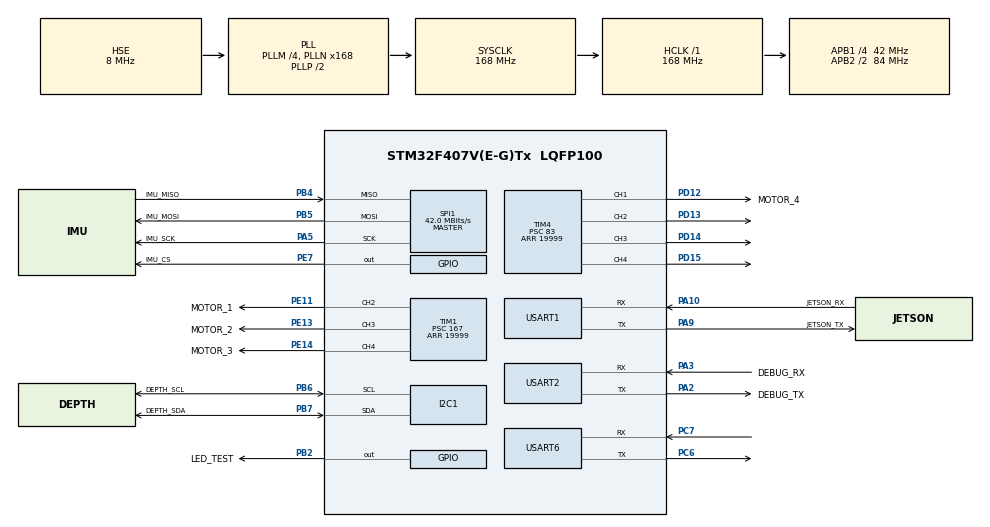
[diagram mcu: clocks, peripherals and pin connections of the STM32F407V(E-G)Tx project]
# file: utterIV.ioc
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Dma.Request0=USART1_TX
Dma.USART1_TX.0.Direction=DMA_MEMORY_TO_PERIPH
Dma.USART1_TX.0.FIFOMode=DMA_FIFOMODE_DISABLE
Dma.USART1_TX.0.Instance=DMA2_Stream7
Dma.USART1_TX.0.MemDataAlignment=DMA_MDATAALIGN_BYTE
Dma.USART1_TX.0.MemInc=DMA_MINC_ENABLE
Dma.USART1_TX.0.Mode=DMA_NORMAL
Dma.USART1_TX.0.PeriphDataAlignment=DMA_PDATAALIGN_BYTE
Dma.USART1_TX.0.PeriphInc=DMA_PINC_DISABLE
Dma.USART1_TX.0.Priority=DMA_PRIORITY_LOW
FREERTOS.Tasks01=startTask,24,300,StartDefaultTask,Default,NULL,Dynamic,NULL,NULL
FREERTOS.configENABLE_FPU=0
Mcu.Family=STM32F4
Mcu.Name=STM32F407V(E-G)Tx
Mcu.Package=LQFP100
NVIC.DMA2_Stream7_IRQn=true\:5\:0\:false\:false\:true\:true\:false\:true\:true
NVIC.PriorityGroup=NVIC_PRIORITYGROUP_4
NVIC.TIM5_IRQn=true\:15\:0\:false\:false\:true\:false\:false\:true\:true
NVIC.TimeBase=TIM5_IRQn
NVIC.TimeBaseIP=TIM5
NVIC.USART1_IRQn=true\:5\:0\:false\:false\:true\:true\:true\:true\:true
NVIC.USART6_IRQn=true\:5\:0\:false\:false\:true\:true\:true\:true\:true
PA10.GPIO_Label=JETSON_RX
PA10.Mode=Asynchronous
PA10.Signal=USART1_RX
PA13.Mode=Serial_Wire
PA13.Signal=SYS_JTMS-SWDIO
PA14.Mode=Serial_Wire
PA14.Signal=SYS_JTCK-SWCLK
PA2.GPIO_Label=DEBUG_TX
PA2.Mode=Asynchronous
PA2.Signal=USART2_TX
PA3.GPIO_Label=DEBUG_RX
PA3.Mode=Asynchronous
PA3.Signal=USART2_RX
PA5.GPIO_Label=IMU_SCK
PA5.Mode=Full_Duplex_Master
PA5.Signal=SPI1_SCK
PA9.GPIO_Label=JETSON_TX
PA9.Mode=Asynchronous
PA9.Signal=USART1_TX
PB2.GPIO_Label=LED_TEST
PB2.PinState=GPIO_PIN_SET
PB2.Signal=GPIO_Output
PB4.GPIO_Label=IMU_MISO
PB4.Mode=Full_Duplex_Master
PB4.Signal=SPI1_MISO
PB5.GPIO_Label=IMU_MOSI
PB5.Mode=Full_Duplex_Master
PB5.Signal=SPI1_MOSI
PB6.GPIO_Label=DEPTH_SCL
PB6.GPIO_Pu=GPIO_NOPULL
PB6.Mode=I2C
PB6.Signal=I2C1_SCL
PB7.GPIO_Label=DEPTH_SDA
PB7.GPIO_Pu=GPIO_NOPULL
PB7.Mode=I2C
PB7.Signal=I2C1_SDA
PC14-OSC32_IN.Mode=LSE-External-Oscillator
PC14-OSC32_IN.Signal=RCC_OSC32_IN
PC15-OSC32_OUT.Mode=LSE-External-Oscillator
PC15-OSC32_OUT.Signal=RCC_OSC32_OUT
PC6.Mode=Asynchronous
PC6.Signal=USART6_TX
PC7.Mode=Asynchronous
PC7.Signal=USART6_RX
PD12.GPIO_Label=MOTOR_4
PD12.Signal=S_TIM4_CH1
PD13.Signal=S_TIM4_CH2
PD14.Signal=S_TIM4_CH3
PD15.Signal=S_TIM4_CH4
PE11.GPIO_Label=MOTOR_1
PE11.Signal=S_TIM1_CH2
PE13.GPIO_Label=MOTOR_2
PE13.Signal=S_TIM1_CH3
PE14.GPIO_Label=MOTOR_3
PE14.Signal=S_TIM1_CH4
PE7.GPIO_Label=IMU_CS
PE7.GPIO_PuPd=GPIO_PULLUP
PE7.PinState=GPIO_PIN_SET
PE7.Signal=GPIO_Output
PH0-OSC_IN.Mode=HSE-External-Oscillator
PH0-OSC_IN.Signal=RCC_OSC_IN
PH1-OSC_OUT.Mode=HSE-External-Oscillator
PH1-OSC_OUT.Signal=RCC_OSC_OUT
ProjectManager.HeapSize=0x200
ProjectManager.StackSize=0x400
ProjectManager.TargetToolchain=MDK-ARM V5.32
RCC.48MHZClocksFreq_Value=84000000
RCC.AHBFreq_Value=168000000
RCC.APB1CLKDivider=RCC_HCLK_DIV4
RCC.APB1Freq_Value=42000000
RCC.APB1TimFreq_Value=84000000
RCC.APB2CLKDivider=RCC_HCLK_DIV2
RCC.APB2Freq_Value=84000000
RCC.APB2TimFreq_Value=168000000
RCC.CortexFreq_Value=168000000
RCC.HCLKFreq_Value=168000000
RCC.HSE_VALUE=8000000
RCC.HSI_VALUE=16000000
RCC.PLLM=4
RCC.PLLN=168
RCC.PLLSourceVirtual=RCC_PLLSOURCE_HSE
RCC.SYSCLKFreq_VALUE=168000000
RCC.SYSCLKSource=RCC_SYSCLKSOURCE_PLLCLK
RCC.VCOOutputFreq_Value=336000000
SH.S_TIM1_CH2.0=TIM1_CH2,PWM Generation2 CH2
SH.S_TIM1_CH3.0=TIM1_CH3,PWM Generation3 CH3
SH.S_TIM1_CH4.0=TIM1_CH4,PWM Generation4 CH4
SH.S_TIM4_CH1.0=TIM4_CH1,PWM Generation1 CH1
SH.S_TIM4_CH2.0=TIM4_CH2,PWM Generation2 CH2
SH.S_TIM4_CH3.0=TIM4_CH3,PWM Generation3 CH3
SH.S_TIM4_CH4.0=TIM4_CH4,PWM Generation4 CH4
SPI1.BaudRatePrescaler=SPI_BAUDRATEPRESCALER_2
SPI1.CalculateBaudRate=42.0 MBits/s
SPI1.Direction=SPI_DIRECTION_2LINES
SPI1.Mode=SPI_MODE_MASTER
SPI1.VirtualType=VM_MASTER
TIM1.AutoReloadPreload=TIM_AUTORELOAD_PRELOAD_ENABLE
TIM1.Channel-PWM\ Generation2\ CH2=TIM_CHANNEL_2
TIM1.Channel-PWM\ Generation3\ CH3=TIM_CHANNEL_3
TIM1.Channel-PWM\ Generation4\ CH4=TIM_CHANNEL_4
TIM1.Period=19999
TIM1.Prescaler=167
TIM1.Pulse-PWM\ Generation2\ CH2=1500
TIM1.Pulse-PWM\ Generation3\ CH3=1500
TIM1.Pulse-PWM\ Generation4\ CH4=1500
TIM4.Channel-PWM\ Generation1\ CH1=TIM_CHANNEL_1
TIM4.Channel-PWM\ Generation2\ CH2=TIM_CHANNEL_2
TIM4.Channel-PWM\ Generation3\ CH3=TIM_CHANNEL_3
TIM4.Channel-PWM\ Generation4\ CH4=TIM_CHANNEL_4
TIM4.Period=19999
TIM4.Prescaler=83
TIM4.Pulse-PWM\ Generation1\ CH1=1500
TIM4.Pulse-PWM\ Generation2\ CH2=1500
TIM4.Pulse-PWM\ Generation3\ CH3=1500
TIM4.Pulse-PWM\ Generation4\ CH4=1500
USART1.VirtualMode=VM_ASYNC
USART2.VirtualMode=VM_ASYNC
USART6.VirtualMode=VM_ASYNC
VP_FREERTOS_VS_CMSIS_V2.Mode=CMSIS_V2
VP_SYS_VS_tim5.Mode=TIM5
board=custom

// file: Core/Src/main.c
/* USER CODE BEGIN Header */
/**
  ******************************************************************************
  * @file           : main.c
  * @brief          : Main program body
  ******************************************************************************
  * @attention
  *
  * Copyright (c) 2026 STMicroelectronics.
  * All rights reserved.
  *
  * This software is licensed under terms that can be found in the LICENSE file
  * in the root directory of this software component.
  * If no LICENSE file comes with this software, it is provided AS-IS.
  *
  ******************************************************************************
  */
/* USER CODE END Header */
#include "main.h"
#include "cmsis_os.h"

/* USER CODE BEGIN Includes */

#include "system.h"

/* USER CODE END Includes */

/* USER CODE BEGIN PM */
#include <stdio.h>

#pragma import(__use_no_semihosting)
struct __FILE { int handle; };
FILE __stdout;
void _sys_exit(int return_code)
{
    while(1);
}

/* USER CODE END PM */

I2C_HandleTypeDef hi2c1;

SPI_HandleTypeDef hspi1;

TIM_HandleTypeDef htim1;
TIM_HandleTypeDef htim4;

UART_HandleTypeDef huart1;
UART_HandleTypeDef huart2;
UART_HandleTypeDef huart6;
DMA_HandleTypeDef hdma_usart1_tx;

/* Definitions for startTask */
osThreadId_t startTaskHandle;
const osThreadAttr_t startTask_attributes = {
  .name = "startTask",
  .stack_size = 300 * 4,
  .priority = (osPriority_t) osPriorityNormal,
};

void SystemClock_Config(void);
static void MX_GPIO_Init(void);
static void MX_DMA_Init(void);
static void MX_SPI1_Init(void);
static void MX_TIM1_Init(void);
static void MX_USART1_UART_Init(void);
static void MX_USART2_UART_Init(void);
static void MX_TIM4_Init(void);
static void MX_I2C1_Init(void);
static void MX_USART6_UART_Init(void);
void StartDefaultTask(void *argument);

/* USER CODE BEGIN 0 */
//int fputc(int ch, FILE *f)
//{
//    HAL_UART_Transmit(&huart1, (uint8_t *)&ch, 1, HAL_MAX_DELAY);
//    return ch;
//}
/* USER CODE END 0 */

int main(void)
{

  /* MCU Configuration--------------------------------------------------------*/

  /* Reset of all peripherals, Initializes the Flash interface and the Systick. */
  HAL_Init();

  /* Configure the system clock */
  SystemClock_Config();

  /* Initialize all configured peripherals */
  MX_GPIO_Init();
  MX_DMA_Init();
  MX_SPI1_Init();
  MX_TIM1_Init();
  MX_USART1_UART_Init();
  MX_USART2_UART_Init();
  MX_TIM4_Init();
  MX_I2C1_Init();
  MX_USART6_UART_Init();
  /* USER CODE BEGIN 2 */
  systemInit();

  /* USER CODE END 2 */

  /* Init scheduler */
  osKernelInitialize();

  /* Create the thread(s) */
  /* creation of startTask */
  startTaskHandle = osThreadNew(StartDefaultTask, NULL, &startTask_attributes);

  /* Start scheduler */
  osKernelStart();

  /* We should never get here as control is now taken by the scheduler */

  /* Infinite loop */
  while (1)
  {

  }
}

void SystemClock_Config(void)
{
  RCC_OscInitTypeDef RCC_OscInitStruct = {0};
  RCC_ClkInitTypeDef RCC_ClkInitStruct = {0};

  /** Configure the main internal regulator output voltage
  */
  __HAL_RCC_PWR_CLK_ENABLE();
  __HAL_PWR_VOLTAGESCALING_CONFIG(PWR_REGULATOR_VOLTAGE_SCALE1);

  /** Initializes the RCC Oscillators according to the specified parameters
  * in the RCC_OscInitTypeDef structure.
  */
  RCC_OscInitStruct.OscillatorType = RCC_OSCILLATORTYPE_HSE;
  RCC_OscInitStruct.HSEState = RCC_HSE_ON;
  RCC_OscInitStruct.PLL.PLLState = RCC_PLL_ON;
  RCC_OscInitStruct.PLL.PLLSource = RCC_PLLSOURCE_HSE;
  RCC_OscInitStruct.PLL.PLLM = 4;
  RCC_OscInitStruct.PLL.PLLN = 168;
  RCC_OscInitStruct.PLL.PLLP = RCC_PLLP_DIV2;
  RCC_OscInitStruct.PLL.PLLQ = 4;
  if (HAL_RCC_OscConfig(&RCC_OscInitStruct) != HAL_OK)
  {
    Error_Handler();
  }

  /** Initializes the CPU, AHB and APB buses clocks
  */
  RCC_ClkInitStruct.ClockType = RCC_CLOCKTYPE_HCLK|RCC_CLOCKTYPE_SYSCLK
                              |RCC_CLOCKTYPE_PCLK1|RCC_CLOCKTYPE_PCLK2;
  RCC_ClkInitStruct.SYSCLKSource = RCC_SYSCLKSOURCE_PLLCLK;
  RCC_ClkInitStruct.AHBCLKDivider = RCC_SYSCLK_DIV1;
  RCC_ClkInitStruct.APB1CLKDivider = RCC_HCLK_DIV4;
  RCC_ClkInitStruct.APB2CLKDivider = RCC_HCLK_DIV2;

  if (HAL_RCC_ClockConfig(&RCC_ClkInitStruct, FLASH_LATENCY_5) != HAL_OK)
  {
    Error_Handler();
  }
}

static void MX_I2C1_Init(void)
{

  hi2c1.Instance = I2C1;
  hi2c1.Init.ClockSpeed = 100000;
  hi2c1.Init.DutyCycle = I2C_DUTYCYCLE_2;
  hi2c1.Init.OwnAddress1 = 0;
  hi2c1.Init.AddressingMode = I2C_ADDRESSINGMODE_7BIT;
  hi2c1.Init.DualAddressMode = I2C_DUALADDRESS_DISABLE;
  hi2c1.Init.OwnAddress2 = 0;
  hi2c1.Init.GeneralCallMode = I2C_GENERALCALL_DISABLE;
  hi2c1.Init.NoStretchMode = I2C_NOSTRETCH_DISABLE;
  if (HAL_I2C_Init(&hi2c1) != HAL_OK)
  {
    Error_Handler();
  }

}

static void MX_SPI1_Init(void)
{

  /* SPI1 parameter configuration*/
  hspi1.Instance = SPI1;
  hspi1.Init.Mode = SPI_MODE_MASTER;
  hspi1.Init.Direction = SPI_DIRECTION_2LINES;
  hspi1.Init.DataSize = SPI_DATASIZE_8BIT;
  hspi1.Init.CLKPolarity = SPI_POLARITY_LOW;
  hspi1.Init.CLKPhase = SPI_PHASE_1EDGE;
  hspi1.Init.NSS = SPI_NSS_SOFT;
  hspi1.Init.BaudRatePrescaler = SPI_BAUDRATEPRESCALER_2;
  hspi1.Init.FirstBit = SPI_FIRSTBIT_MSB;
  hspi1.Init.TIMode = SPI_TIMODE_DISABLE;
  hspi1.Init.CRCCalculation = SPI_CRCCALCULATION_DISABLE;
  hspi1.Init.CRCPolynomial = 10;
  if (HAL_SPI_Init(&hspi1) != HAL_OK)
  {
    Error_Handler();
  }

}

static void MX_TIM1_Init(void)
{

  TIM_MasterConfigTypeDef sMasterConfig = {0};
  TIM_OC_InitTypeDef sConfigOC = {0};
  TIM_BreakDeadTimeConfigTypeDef sBreakDeadTimeConfig = {0};

  htim1.Instance = TIM1;
  htim1.Init.Prescaler = 167;
  htim1.Init.CounterMode = TIM_COUNTERMODE_UP;
  htim1.Init.Period = 19999;
  htim1.Init.ClockDivision = TIM_CLOCKDIVISION_DIV1;
  htim1.Init.RepetitionCounter = 0;
  htim1.Init.AutoReloadPreload = TIM_AUTORELOAD_PRELOAD_ENABLE;
  if (HAL_TIM_PWM_Init(&htim1) != HAL_OK)
  {
    Error_Handler();
  }
  sMasterConfig.MasterOutputTrigger = TIM_TRGO_RESET;
  sMasterConfig.MasterSlaveMode = TIM_MASTERSLAVEMODE_DISABLE;
  if (HAL_TIMEx_MasterConfigSynchronization(&htim1, &sMasterConfig) != HAL_OK)
  {
    Error_Handler();
  }
  sConfigOC.OCMode = TIM_OCMODE_PWM1;
  sConfigOC.Pulse = 1500;
  sConfigOC.OCPolarity = TIM_OCPOLARITY_HIGH;
  sConfigOC.OCNPolarity = TIM_OCNPOLARITY_HIGH;
  sConfigOC.OCFastMode = TIM_OCFAST_DISABLE;
  sConfigOC.OCIdleState = TIM_OCIDLESTATE_RESET;
  sConfigOC.OCNIdleState = TIM_OCNIDLESTATE_RESET;
  if (HAL_TIM_PWM_ConfigChannel(&htim1, &sConfigOC, TIM_CHANNEL_2) != HAL_OK)
  {
    Error_Handler();
  }
  if (HAL_TIM_PWM_ConfigChannel(&htim1, &sConfigOC, TIM_CHANNEL_3) != HAL_OK)
  {
    Error_Handler();
  }
  if (HAL_TIM_PWM_ConfigChannel(&htim1, &sConfigOC, TIM_CHANNEL_4) != HAL_OK)
  {
    Error_Handler();
  }
  sBreakDeadTimeConfig.OffStateRunMode = TIM_OSSR_DISABLE;
  sBreakDeadTimeConfig.OffStateIDLEMode = TIM_OSSI_DISABLE;
  sBreakDeadTimeConfig.LockLevel = TIM_LOCKLEVEL_OFF;
  sBreakDeadTimeConfig.DeadTime = 0;
  sBreakDeadTimeConfig.BreakState = TIM_BREAK_DISABLE;
  sBreakDeadTimeConfig.BreakPolarity = TIM_BREAKPOLARITY_HIGH;
  sBreakDeadTimeConfig.AutomaticOutput = TIM_AUTOMATICOUTPUT_DISABLE;
  if (HAL_TIMEx_ConfigBreakDeadTime(&htim1, &sBreakDeadTimeConfig) != HAL_OK)
  {
    Error_Handler();
  }
  HAL_TIM_MspPostInit(&htim1);

}

static void MX_TIM4_Init(void)
{

  TIM_MasterConfigTypeDef sMasterConfig = {0};
  TIM_OC_InitTypeDef sConfigOC = {0};

  htim4.Instance = TIM4;
  htim4.Init.Prescaler = 83;
  htim4.Init.CounterMode = TIM_COUNTERMODE_UP;
  htim4.Init.Period = 19999;
  htim4.Init.ClockDivision = TIM_CLOCKDIVISION_DIV1;
  htim4.Init.AutoReloadPreload = TIM_AUTORELOAD_PRELOAD_DISABLE;
  if (HAL_TIM_PWM_Init(&htim4) != HAL_OK)
  {
    Error_Handler();
  }
  sMasterConfig.MasterOutputTrigger = TIM_TRGO_RESET;
  sMasterConfig.MasterSlaveMode = TIM_MASTERSLAVEMODE_DISABLE;
  if (HAL_TIMEx_MasterConfigSynchronization(&htim4, &sMasterConfig) != HAL_OK)
  {
    Error_Handler();
  }
  sConfigOC.OCMode = TIM_OCMODE_PWM1;
  sConfigOC.Pulse = 1500;
  sConfigOC.OCPolarity = TIM_OCPOLARITY_HIGH;
  sConfigOC.OCFastMode = TIM_OCFAST_DISABLE;
  if (HAL_TIM_PWM_ConfigChannel(&htim4, &sConfigOC, TIM_CHANNEL_1) != HAL_OK)
  {
    Error_Handler();
  }
  if (HAL_TIM_PWM_ConfigChannel(&htim4, &sConfigOC, TIM_CHANNEL_2) != HAL_OK)
  {
    Error_Handler();
  }
  if (HAL_TIM_PWM_ConfigChannel(&htim4, &sConfigOC, TIM_CHANNEL_3) != HAL_OK)
  {
    Error_Handler();
  }
  if (HAL_TIM_PWM_ConfigChannel(&htim4, &sConfigOC, TIM_CHANNEL_4) != HAL_OK)
  {
    Error_Handler();
  }
  HAL_TIM_MspPostInit(&htim4);

}

static void MX_USART1_UART_Init(void)
{

  huart1.Instance = USART1;
  huart1.Init.BaudRate = 115200;
  huart1.Init.WordLength = UART_WORDLENGTH_8B;
  huart1.Init.StopBits = UART_STOPBITS_1;
  huart1.Init.Parity = UART_PARITY_NONE;
  huart1.Init.Mode = UART_MODE_TX_RX;
  huart1.Init.HwFlowCtl = UART_HWCONTROL_NONE;
  huart1.Init.OverSampling = UART_OVERSAMPLING_16;
  if (HAL_UART_Init(&huart1) != HAL_OK)
  {
    Error_Handler();
  }

}

static void MX_USART2_UART_Init(void)
{

  huart2.Instance = USART2;
  huart2.Init.BaudRate = 115200;
  huart2.Init.WordLength = UART_WORDLENGTH_8B;
  huart2.Init.StopBits = UART_STOPBITS_1;
  huart2.Init.Parity = UART_PARITY_NONE;
  huart2.Init.Mode = UART_MODE_TX_RX;
  huart2.Init.HwFlowCtl = UART_HWCONTROL_NONE;
  huart2.Init.OverSampling = UART_OVERSAMPLING_16;
  if (HAL_UART_Init(&huart2) != HAL_OK)
  {
    Error_Handler();
  }

}

static void MX_USART6_UART_Init(void)
{

  huart6.Instance = USART6;
  huart6.Init.BaudRate = 115200;
  huart6.Init.WordLength = UART_WORDLENGTH_8B;
  huart6.Init.StopBits = UART_STOPBITS_1;
  huart6.Init.Parity = UART_PARITY_NONE;
  huart6.Init.Mode = UART_MODE_TX_RX;
  huart6.Init.HwFlowCtl = UART_HWCONTROL_NONE;
  huart6.Init.OverSampling = UART_OVERSAMPLING_16;
  if (HAL_UART_Init(&huart6) != HAL_OK)
  {
    Error_Handler();
  }

}

static void MX_DMA_Init(void)
{

  /* DMA controller clock enable */
  __HAL_RCC_DMA2_CLK_ENABLE();

  /* DMA interrupt init */
  /* DMA2_Stream7_IRQn interrupt configuration */
  HAL_NVIC_SetPriority(DMA2_Stream7_IRQn, 5, 0);
  HAL_NVIC_EnableIRQ(DMA2_Stream7_IRQn);

}

static void MX_GPIO_Init(void)
{
  GPIO_InitTypeDef GPIO_InitStruct = {0};

  /* GPIO Ports Clock Enable */
  __HAL_RCC_GPIOC_CLK_ENABLE();
  __HAL_RCC_GPIOH_CLK_ENABLE();
  __HAL_RCC_GPIOA_CLK_ENABLE();
  __HAL_RCC_GPIOB_CLK_ENABLE();
  __HAL_RCC_GPIOE_CLK_ENABLE();
  __HAL_RCC_GPIOD_CLK_ENABLE();

  /*Configure GPIO pin Output Level */
  HAL_GPIO_WritePin(LED_TEST_GPIO_Port, LED_TEST_Pin, GPIO_PIN_SET);

  /*Configure GPIO pin Output Level */
  HAL_GPIO_WritePin(IMU_CS_GPIO_Port, IMU_CS_Pin, GPIO_PIN_SET);

  /*Configure GPIO pin : LED_TEST_Pin */
  GPIO_InitStruct.Pin = LED_TEST_Pin;
  GPIO_InitStruct.Mode = GPIO_MODE_OUTPUT_PP;
  GPIO_InitStruct.Pull = GPIO_NOPULL;
  GPIO_InitStruct.Speed = GPIO_SPEED_FREQ_LOW;
  HAL_GPIO_Init(LED_TEST_GPIO_Port, &GPIO_InitStruct);

  /*Configure GPIO pin : IMU_CS_Pin */
  GPIO_InitStruct.Pin = IMU_CS_Pin;
  GPIO_InitStruct.Mode = GPIO_MODE_OUTPUT_PP;
  GPIO_InitStruct.Pull = GPIO_PULLUP;
  GPIO_InitStruct.Speed = GPIO_SPEED_FREQ_LOW;
  HAL_GPIO_Init(IMU_CS_GPIO_Port, &GPIO_InitStruct);

}

void StartDefaultTask(void *argument)
{
  /* USER CODE BEGIN 5 */

	xTaskCreate(jetsonLinkTask, "JETSON_LINK", 400, NULL, 6, NULL);
	xTaskCreate(uwbTask, "UWB", 500, NULL, 4, NULL);
	xTaskCreate(depthTask, "DEPTH", 400, NULL, 3, NULL);
	xTaskCreate(imuTask, "IMU", 450, NULL, 4, NULL);
	xTaskCreate(stabilizerTask, "STABILIZER", 450, NULL, 5, NULL);

	vTaskDelete(NULL);

  /* Infinite loop */

  /* USER CODE END 5 */
}

void HAL_TIM_PeriodElapsedCallback(TIM_HandleTypeDef *htim)
{
  if (htim->Instance == TIM5)
  {
    HAL_IncTick();
  }
}

void Error_Handler(void)
{
  __disable_irq();
  while (1)
  {
  }
}
